# STM32H753ZIT6 register map
File version: 1.0
Registers are 32-bit, access not given, reset 0x0 unless marked. A register's access mark holds for its fields unless they carry their own. Offsets are from the block's base; [hi:lo] are bit positions; {n}, {i} and the like mark numbered series; 'fields as' and 'values as' point back to an identical list.

## FMC_Bank1E_R
Base 0x52004104
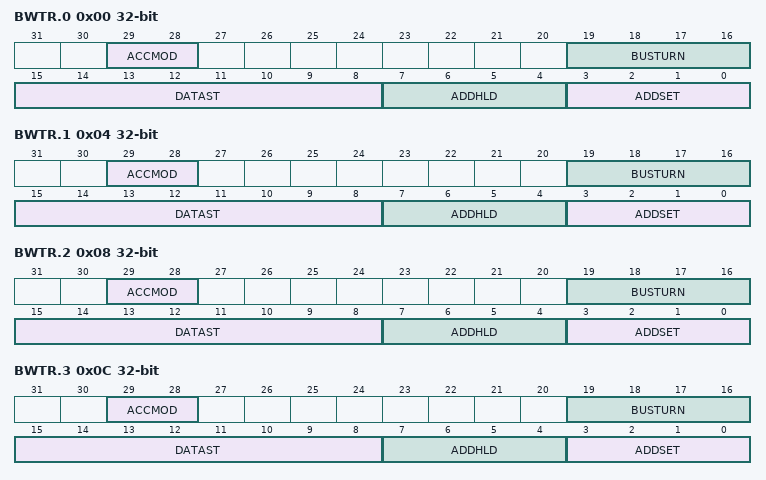
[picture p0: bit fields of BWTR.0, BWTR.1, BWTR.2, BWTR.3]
0x00 BWTR.0
  [29:28] ACCMOD, [19:16] BUSTURN, [15:8] DATAST, [7:4] ADDHLD, [3:0] ADDSET
0x04 BWTR.1
  fields as BWTR.0
0x08 BWTR.2
  fields as BWTR.0
0x0C BWTR.3
  fields as BWTR.0
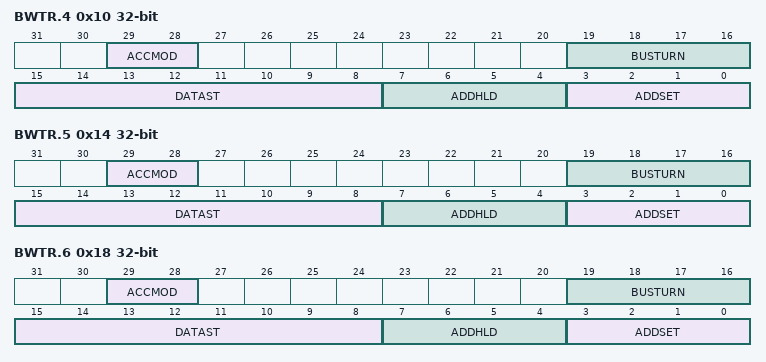
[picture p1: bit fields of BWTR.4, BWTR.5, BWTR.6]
0x10 BWTR.4
  fields as BWTR.0
0x14 BWTR.5
  fields as BWTR.0
0x18 BWTR.6
  fields as BWTR.0

## FMC_Bank5_6_R
Base 0x52004140
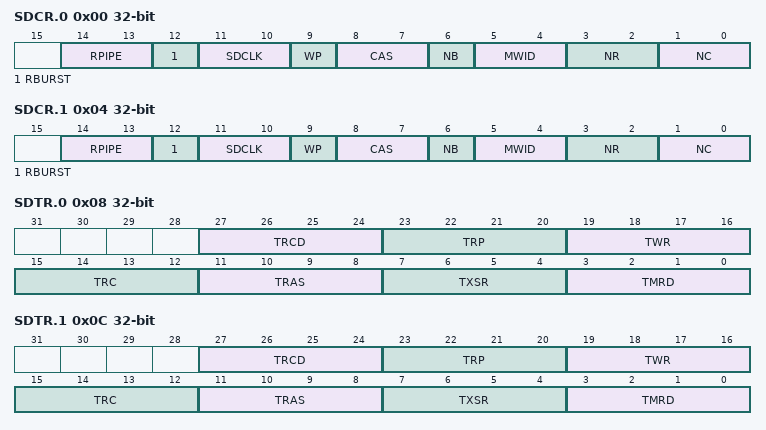
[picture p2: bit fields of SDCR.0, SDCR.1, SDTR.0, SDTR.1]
0x00 SDCR.0
  [14:13] RPIPE, [12] RBURST, [11:10] SDCLK, [9] WP, [8:7] CAS, [6] NB, [5:4] MWID, [3:2] NR, [1:0] NC
0x04 SDCR.1
  fields as SDCR.0
0x08 SDTR.0
  [27:24] TRCD, [23:20] TRP, [19:16] TWR, [15:12] TRC, [11:8] TRAS, [7:4] TXSR, [3:0] TMRD
0x0C SDTR.1
  fields as SDTR.0
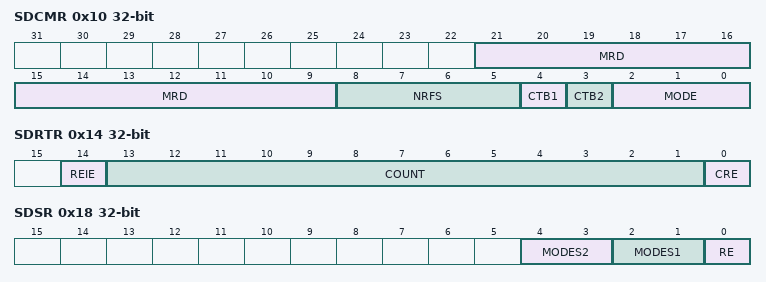
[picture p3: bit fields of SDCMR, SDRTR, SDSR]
0x10 SDCMR
  [21:9] MRD, [8:5] NRFS, [4] CTB1, [3] CTB2, [2:0] MODE
0x14 SDRTR
  [14] REIE, [13:1] COUNT, [0] CRE
0x18 SDSR
  [4:3] MODES2, [2:1] MODES1, [0] RE

## QUADSPI
Base 0x52005000
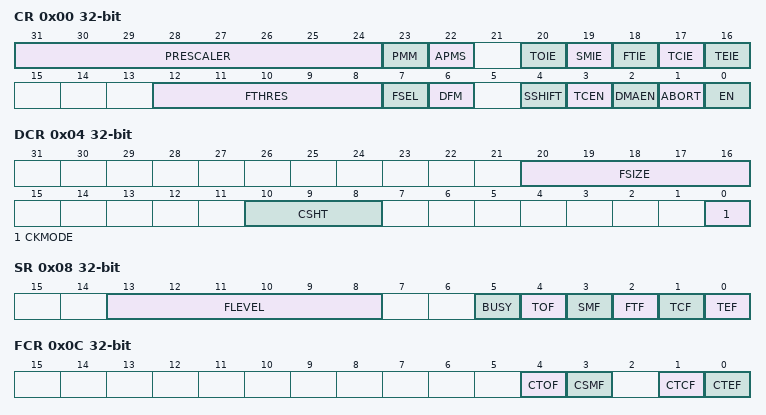
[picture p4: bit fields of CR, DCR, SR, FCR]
0x00 CR
  [31:24] PRESCALER, [23] PMM, [22] APMS, [20] TOIE, [19] SMIE, [18] FTIE, [17] TCIE, [16] TEIE, [12:8] FTHRES, [7] FSEL, [6] DFM, [4] SSHIFT, [3] TCEN, [2] DMAEN, [1] ABORT, [0] EN
0x04 DCR
  [20:16] FSIZE, [10:8] CSHT, [0] CKMODE
0x08 SR
  [13:8] FLEVEL, [5] BUSY, [4] TOF, [3] SMF, [2] FTF, [1] TCF, [0] TEF
0x0C FCR
  [4] CTOF, [3] CSMF, [1] CTCF, [0] CTEF
0x10 DLR
  [31:0] DL
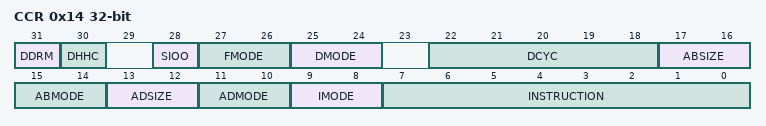
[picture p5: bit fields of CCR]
0x14 CCR
  [31] DDRM, [30] DHHC, [28] SIOO, [27:26] FMODE, [25:24] DMODE, [22:18] DCYC, [17:16] ABSIZE, [15:14] ABMODE, [13:12] ADSIZE, [11:10] ADMODE, [9:8] IMODE, [7:0] INSTRUCTION
0x18 AR
  [31:0] ADDRESS
0x1C ABR
  [31:0] ALTERNATE
0x20 DR
  [31:0] DATA
0x24 PSMKR
  [31:0] MASK
0x28 PSMAR
  [31:0] MATCH
0x2C PIR
  [15:0] INTERVAL
0x30 LPTR
  [15:0] TIMEOUT

## EXTI
Base 0x58000000
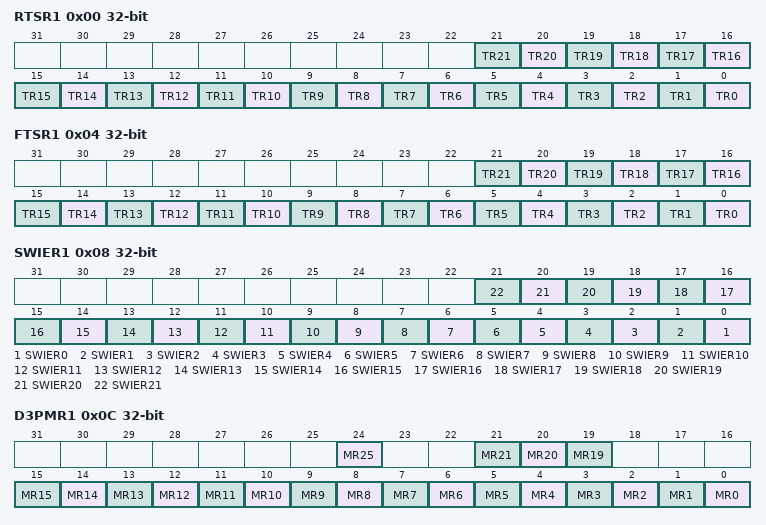
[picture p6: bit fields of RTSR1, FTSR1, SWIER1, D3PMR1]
0x00 RTSR1
  [n] TR{n} (n=0..21)
0x04 FTSR1
  [n] TR{n} (n=0..21)
0x08 SWIER1
  [n] SWIER{n} (n=0..21)
0x0C D3PMR1
  [24] MR25, [21] MR21, [20] MR20, [19] MR19, [n] MR{n} (n=0..15)
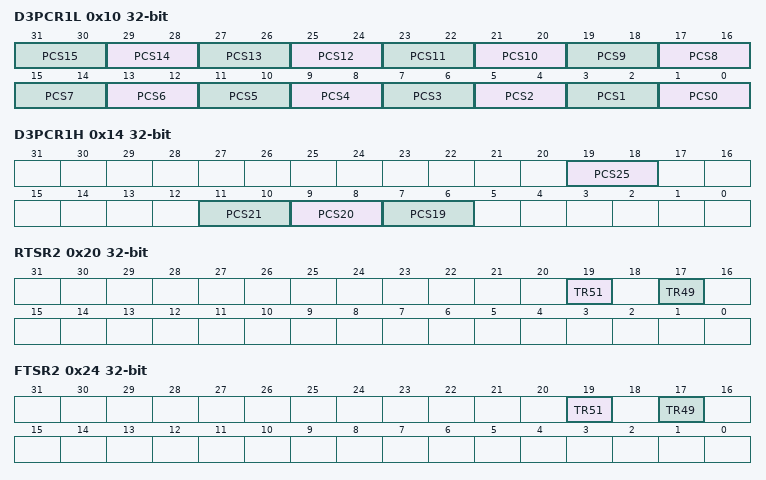
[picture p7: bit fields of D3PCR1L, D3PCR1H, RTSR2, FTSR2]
0x10 D3PCR1L
  [2n+1:2n] PCS{n} (n=0..15)
0x14 D3PCR1H
  [19:18] PCS25, [11:10] PCS21, [9:8] PCS20, [7:6] PCS19
0x20 RTSR2
  [19] TR51, [17] TR49
0x24 FTSR2
  [19] TR51, [17] TR49
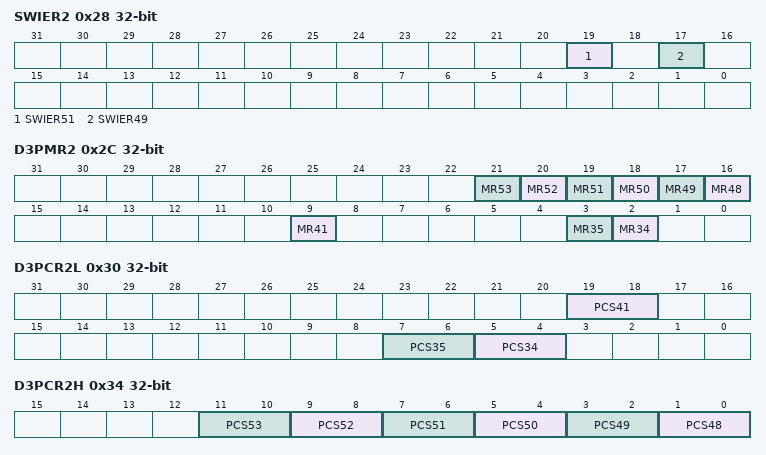
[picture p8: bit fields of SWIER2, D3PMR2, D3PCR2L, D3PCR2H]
0x28 SWIER2
  [19] SWIER51, [17] SWIER49
0x2C D3PMR2
  [n-32] MR{n} (n=48..53), [9] MR41, [3] MR35, [2] MR34
0x30 D3PCR2L
  [19:18] PCS41, [7:6] PCS35, [5:4] PCS34
0x34 D3PCR2H
  [2n-95:2n-96] PCS{n} (n=48..53)
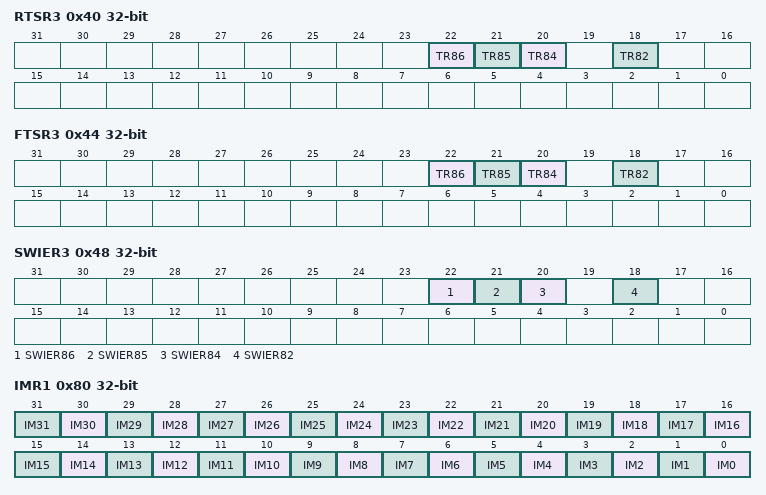
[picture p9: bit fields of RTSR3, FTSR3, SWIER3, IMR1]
0x40 RTSR3
  [22] TR86, [21] TR85, [20] TR84, [18] TR82
0x44 FTSR3
  [22] TR86, [21] TR85, [20] TR84, [18] TR82
0x48 SWIER3
  [22] SWIER86, [21] SWIER85, [20] SWIER84, [18] SWIER82
0x4C D3PMR3
0x50 D3PCR3L
0x54 D3PCR3H
0x80 IMR1
  [n] IM{n} (n=0..31)
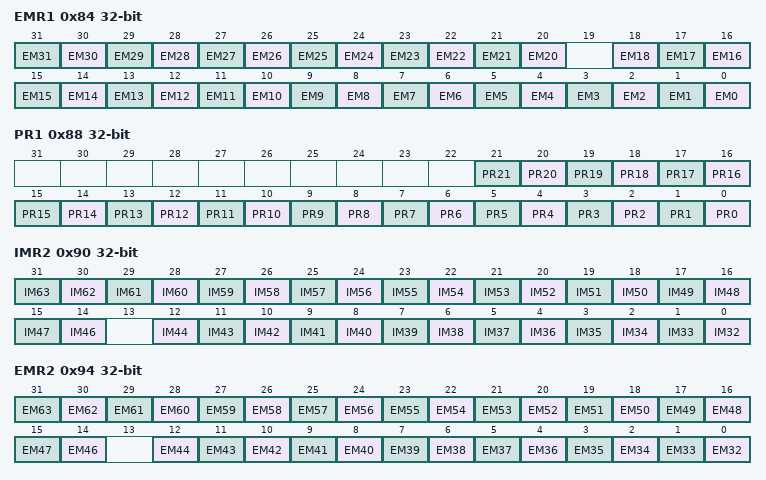
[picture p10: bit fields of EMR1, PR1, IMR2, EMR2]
0x84 EMR1
  [n] EM{n} (n=20..31), [n] EM{n} (n=0..18)
0x88 PR1
  [n] PR{n} (n=0..21)
0x90 IMR2
  [n-32] IM{n} (n=46..63), [n-32] IM{n} (n=32..44)
0x94 EMR2
  [n-32] EM{n} (n=46..63), [n-32] EM{n} (n=32..44)
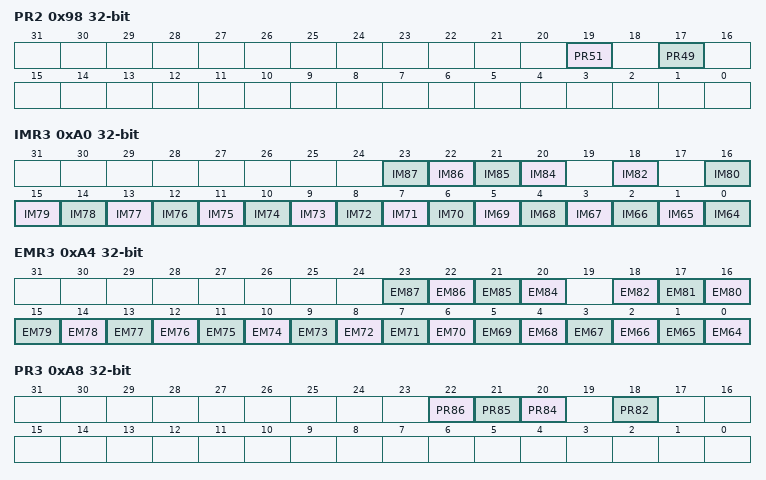
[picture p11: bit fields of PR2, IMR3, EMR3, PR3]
0x98 PR2
  [19] PR51, [17] PR49
0xA0 IMR3
  [n-64] IM{n} (n=84..87), [18] IM82, [n-64] IM{n} (n=64..80)
0xA4 EMR3
  [n-64] EM{n} (n=84..87), [n-64] EM{n} (n=64..82)
0xA8 PR3
  [22] PR86, [21] PR85, [20] PR84, [18] PR82

## EXTI_D1
Base 0x58000080
Same registers: EXTI_D2 0x580000C0
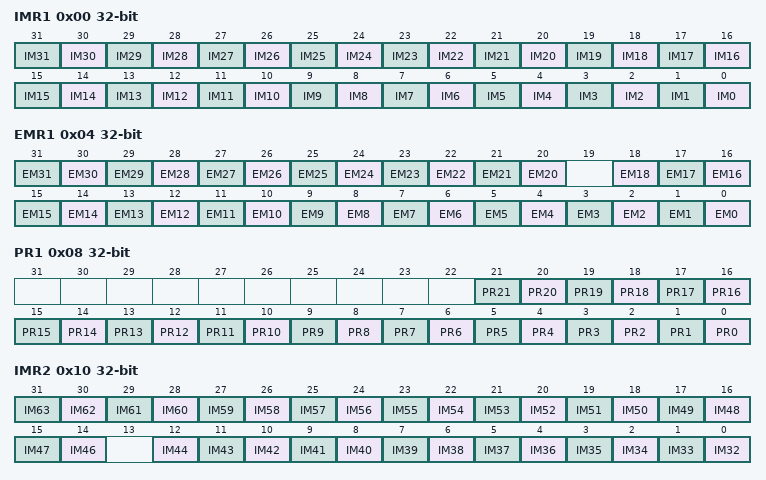
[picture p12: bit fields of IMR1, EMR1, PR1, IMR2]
0x00 IMR1
  [n] IM{n} (n=0..31)
0x04 EMR1
  [n] EM{n} (n=20..31), [n] EM{n} (n=0..18)
0x08 PR1
  [n] PR{n} (n=0..21)
0x10 IMR2
  [n-32] IM{n} (n=46..63), [n-32] IM{n} (n=32..44)
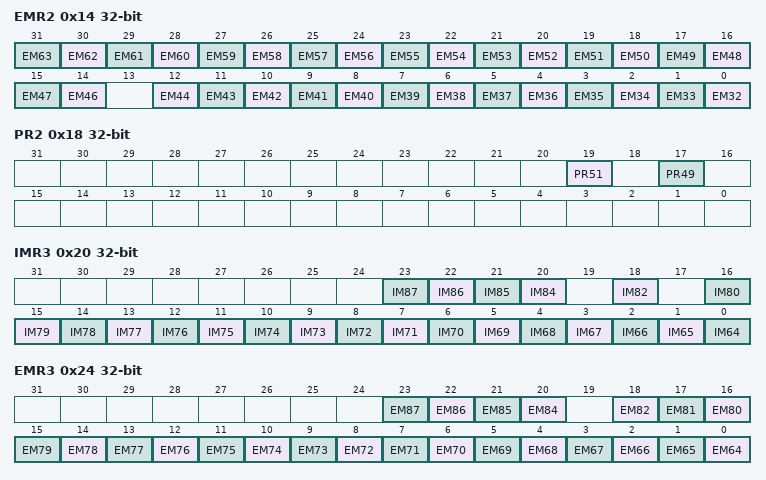
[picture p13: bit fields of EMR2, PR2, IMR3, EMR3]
0x14 EMR2
  [n-32] EM{n} (n=46..63), [n-32] EM{n} (n=32..44)
0x18 PR2
  [19] PR51, [17] PR49
0x20 IMR3
  [n-64] IM{n} (n=84..87), [18] IM82, [n-64] IM{n} (n=64..80)
0x24 EMR3
  [n-64] EM{n} (n=84..87), [n-64] EM{n} (n=64..82)
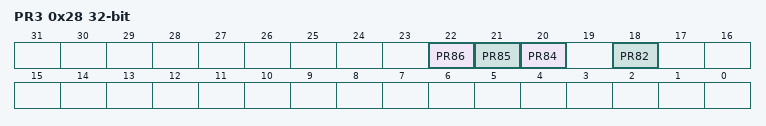
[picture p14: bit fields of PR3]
0x28 PR3
  [22] PR86, [21] PR85, [20] PR84, [18] PR82

## SYSCFG
Base 0x58000400
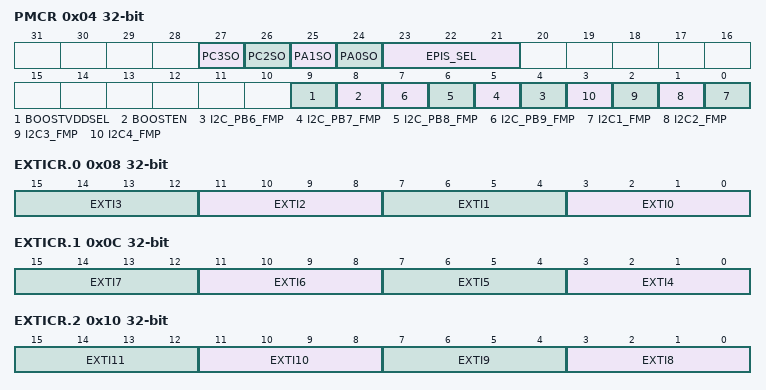
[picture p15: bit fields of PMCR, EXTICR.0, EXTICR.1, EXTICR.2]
0x04 PMCR
  [27] PC3SO, [26] PC2SO, [25] PA1SO, [24] PA0SO, [23:21] EPIS_SEL, [9] BOOSTVDDSEL, [8] BOOSTEN, [n-2] I2C_PB{n}_FMP (n=6..9), [n-1] I2C{n}_FMP (n=1..4)
0x08 EXTICR.0
  [4n+3:4n] EXTI{n} (n=0..3)
0x0C EXTICR.1
  [4n-13:4n-16] EXTI{n} (n=4..7)
0x10 EXTICR.2
  [4n-29:4n-32] EXTI{n} (n=8..11)
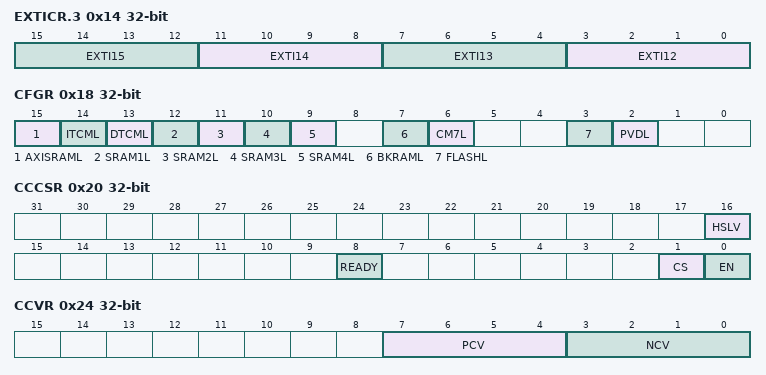
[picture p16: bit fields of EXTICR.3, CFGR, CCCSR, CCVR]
0x14 EXTICR.3
  [4n-45:4n-48] EXTI{n} (n=12..15)
0x18 CFGR
  [15] AXISRAML, [14] ITCML, [13] DTCML, [13-n] SRAM{n}L (n=1..4), [7] BKRAML, [6] CM7L, [3] FLASHL, [2] PVDL
0x20 CCCSR
  [16] HSLV, [8] READY, [1] CS, [0] EN
0x24 CCVR
  [7:4] PCV, [3:0] NCV
0x28 CCCR
  [7:4] PCC, [3:0] NCC
0x2C PWRCR
  [0] ODEN
0x124 PKGR
  [3:0] PKG
0x300 UR0
  [23:16] RDP, [0] BKS
0x304 UR1
0x308 UR2
  [31:16] BOOT_ADD0, [1:0] BORH
0x30C UR3
  [15:0] BOOT_ADD1
0x310 UR4
  [16] MEPAD_BANK1
0x314 UR5
  [23:16] WRPN_BANK1, [0] MESAD_BANK1
0x318 UR6
  [27:16] PAEND_BANK1, [11:0] PABEG_BANK1
0x31C UR7
  [27:16] SAEND_BANK1, [11:0] SABEG_BANK1
0x320 UR8
  [16] MESAD_BANK2, [0] MEPAD_BANK2
0x324 UR9
  [27:16] PABEG_BANK2, [7:0] WRPN_BANK2
0x328 UR10
  [27:16] SABEG_BANK2, [11:0] PAEND_BANK2
0x32C UR11
  [16] IWDG1M, [11:0] SAEND_BANK2
0x330 UR12
  [16] SECURE
0x334 UR13
  [16] D1SBRST, [1:0] SDRS
0x338 UR14
  [0] D1STPRST
0x33C UR15
  [16] FZIWDGSTB
0x340 UR16
  [16] PKP, [0] FZIWDGSTP
0x344 UR17
  [0] IOHSLV
